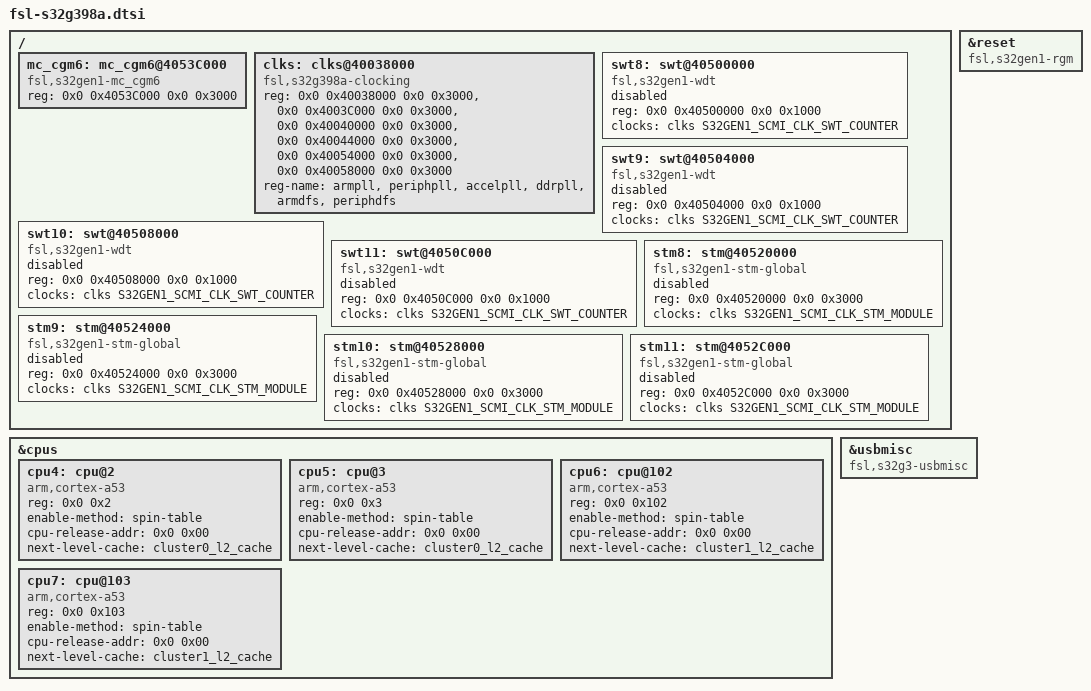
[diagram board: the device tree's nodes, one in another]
// SPDX-License-Identifier: GPL-2.0
/*
 * Copyright 2021 NXP
 *
 * This program is free software; you can redistribute it and/or modify
 * it under the terms of the GNU General Public License as published by
 * the Free Software Foundation; either version 2 of the License, or
 * (at your option) any later version.
 */

/dts-v1/;
#include "fsl-s32g.dtsi"

/ {
	mc_cgm6: mc_cgm6@4053C000 {
		compatible = "fsl,s32gen1-mc_cgm6";
		reg = <0x0 0x4053C000 0x0 0x3000>;
	};

	clks: clks@40038000 {
		compatible = "fsl,s32g398a-clocking";
		reg = <0x0 0x40038000 0x0 0x3000>,
		      <0x0 0x4003C000 0x0 0x3000>,
		      <0x0 0x40040000 0x0 0x3000>,
		      <0x0 0x40044000 0x0 0x3000>,
		      <0x0 0x40054000 0x0 0x3000>,
		      <0x0 0x40058000 0x0 0x3000>;
		reg-name = "armpll", "periphpll", "accelpll",
			   "ddrpll", "armdfs", "periphdfs";
		#clock-cells = <1>;
	};

	swt8: swt@40500000 {
		compatible = "fsl,s32gen1-wdt";
		reg = <0x0 0x40500000 0x0 0x1000>;
		clocks = <&clks S32GEN1_SCMI_CLK_SWT_COUNTER>;
		clock-names = "swt";
		status = "disabled";
	};

	swt9: swt@40504000 {
		compatible = "fsl,s32gen1-wdt";
		reg = <0x0 0x40504000 0x0 0x1000>;
		clocks = <&clks S32GEN1_SCMI_CLK_SWT_COUNTER>;
		clock-names = "swt";
		status = "disabled";
	};

	swt10: swt@40508000 {
		compatible = "fsl,s32gen1-wdt";
		reg = <0x0 0x40508000 0x0 0x1000>;
		clocks = <&clks S32GEN1_SCMI_CLK_SWT_COUNTER>;
		clock-names = "swt";
		status = "disabled";
	};

	swt11: swt@4050C000 {
		compatible = "fsl,s32gen1-wdt";
		reg = <0x0 0x4050C000 0x0 0x1000>;
		clocks = <&clks S32GEN1_SCMI_CLK_SWT_COUNTER>;
		clock-names = "swt";
		status = "disabled";
	};

	stm8: stm@40520000 {
		compatible = "fsl,s32gen1-stm-global";
		reg = <0x0 0x40520000 0x0 0x3000>;
		clocks = <&clks S32GEN1_SCMI_CLK_STM_MODULE>;
		clock-names = "stm";
		status = "disabled";
	};

	stm9: stm@40524000 {
		compatible = "fsl,s32gen1-stm-global";
		reg = <0x0 0x40524000 0x0 0x3000>;
		clocks = <&clks S32GEN1_SCMI_CLK_STM_MODULE>;
		clock-names = "stm";
		status = "disabled";
	};

	stm10: stm@40528000 {
		compatible = "fsl,s32gen1-stm-global";
		reg = <0x0 0x40528000 0x0 0x3000>;
		clocks = <&clks S32GEN1_SCMI_CLK_STM_MODULE>;
		clock-names = "stm";
		status = "disabled";
	};

	stm11: stm@4052C000 {
		compatible = "fsl,s32gen1-stm-global";
		reg = <0x0 0x4052C000 0x0 0x3000>;
		clocks = <&clks S32GEN1_SCMI_CLK_STM_MODULE>;
		clock-names = "stm";
		status = "disabled";
	};
};

&reset {
	compatible = "fsl,s32gen1-rgm", "fsl,s32g3-reset", "syscon";
};

&cpus {
	cpu4: cpu@2 {
		device_type = "cpu";
		compatible = "arm,cortex-a53";
		reg = <0x0 0x2>;
		enable-method = "spin-table";
		cpu-release-addr = <0x0 0x00>;
		next-level-cache = <&cluster0_l2_cache>;
	};
	cpu5: cpu@3 {
		device_type = "cpu";
		compatible = "arm,cortex-a53";
		reg = <0x0 0x3>;
		enable-method = "spin-table";
		cpu-release-addr = <0x0 0x00>;
		next-level-cache = <&cluster0_l2_cache>;
	};
	cpu6: cpu@102 {
		device_type = "cpu";
		compatible = "arm,cortex-a53";
		reg = <0x0 0x102>;
		enable-method = "spin-table";
		cpu-release-addr = <0x0 0x00>;
		next-level-cache = <&cluster1_l2_cache>;
	};
	cpu7: cpu@103 {
		device_type = "cpu";
		compatible = "arm,cortex-a53";
		reg = <0x0 0x103>;
		enable-method = "spin-table";
		cpu-release-addr = <0x0 0x00>;
		next-level-cache = <&cluster1_l2_cache>;
	};
};

&usbmisc {
	compatible = "fsl,s32g3-usbmisc";
};
